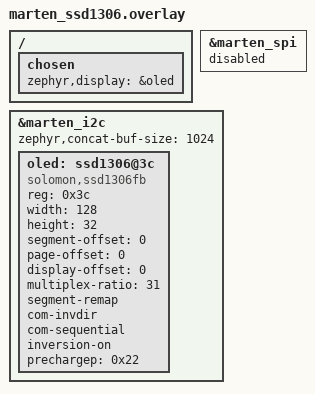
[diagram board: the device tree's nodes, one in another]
&marten_spi {
    status = "disabled";
};

&marten_i2c {
    status = "okay";

    // SSD1306 requires larger buffer.
    zephyr,concat-buf-size = <1024>;

    oled: ssd1306@3c {
        compatible = "solomon,ssd1306fb";
        reg = <0x3c>;
        width = <128>;
        height = <32>;
        segment-offset = <0>;
        page-offset = <0>;
        display-offset = <0>;
        multiplex-ratio = <31>;
        segment-remap;
        com-invdir;
        com-sequential;
        inversion-on;
        prechargep = <0x22>;
    };
};

/{
    chosen {
        zephyr,display = &oled;
    };
};
